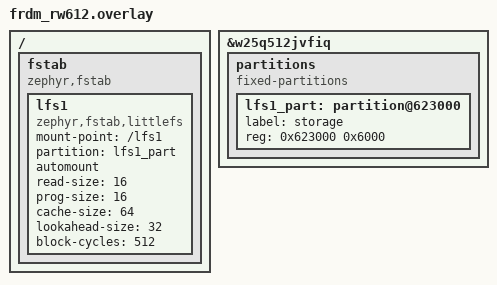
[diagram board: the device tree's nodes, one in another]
/delete-node/ &storage_partition;

/ {
    fstab {
        compatible = "zephyr,fstab";
        lfs1: lfs1 {
            compatible = "zephyr,fstab,littlefs";
            mount-point = "/lfs1";
            partition = <&lfs1_part>;
            automount;
            read-size = <16>;
            prog-size = <16>;
            cache-size = <64>;
            lookahead-size = <32>;
            block-cycles = <512>;
        };
    };
};

&w25q512jvfiq {
    partitions {
        compatible = "fixed-partitions";
        #address-cells = <1>;
        #size-cells = <1>;

        lfs1_part: partition@623000 {
            label = "storage";
            reg = <0x623000 0x6000>;
        };
    };
};
